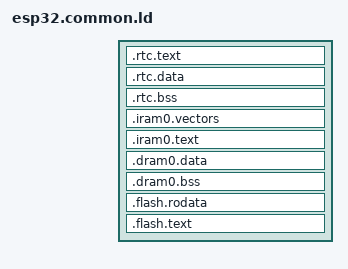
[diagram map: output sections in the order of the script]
/*  Default entry point:  */
ENTRY(call_start_cpu0);

SECTIONS
{
  /* RTC fast memory holds RTC wake stub code,
     including from any source file named rtc_wake_stub*.c
  */
  .rtc.text :
  {
    . = ALIGN(4);
    *(.rtc.literal .rtc.text)
    *rtc_wake_stub*.o(.literal .text .literal.* .text.*)
  } >rtc_iram_seg

  /* RTC slow memory holds RTC wake stub
     data/rodata, including from any source file
     named rtc_wake_stub*.c
  */
  .rtc.data :
  {
    _rtc_data_start = ABSOLUTE(.);
    *(.rtc.data)
    *(.rtc.rodata)
    *rtc_wake_stub*.o(.data .rodata .data.* .rodata.* .bss .bss.*)
    _rtc_data_end = ABSOLUTE(.);
  } > rtc_slow_seg

  /* RTC bss, from any source file named rtc_wake_stub*.c */
  .rtc.bss (NOLOAD) :
  {
    _rtc_bss_start = ABSOLUTE(.);
    *rtc_wake_stub*.o(.bss .bss.*)
    *rtc_wake_stub*.o(COMMON)
    _rtc_bss_end = ABSOLUTE(.);
  } > rtc_slow_seg

  /* Send .iram0 code to iram */
  .iram0.vectors :
  {
    /* Vectors go to IRAM */
    _init_start = ABSOLUTE(.);
    /* Vectors according to builds/RF-2015.2-win32/esp108_v1_2_s5_512int_2/config.html */
    . = 0x0;
    KEEP(*(.WindowVectors.text));
    . = 0x180;
    KEEP(*(.Level2InterruptVector.text));
    . = 0x1c0;
    KEEP(*(.Level3InterruptVector.text));
    . = 0x200;
    KEEP(*(.Level4InterruptVector.text));
    . = 0x240;
    KEEP(*(.Level5InterruptVector.text));
    . = 0x280;
    KEEP(*(.DebugExceptionVector.text));
    . = 0x2c0;
    KEEP(*(.NMIExceptionVector.text));
    . = 0x300;
    KEEP(*(.KernelExceptionVector.text));
    . = 0x340;
    KEEP(*(.UserExceptionVector.text));
    . = 0x3C0;
    KEEP(*(.DoubleExceptionVector.text));
    . = 0x400;
    *(.*Vector.literal)

    *(.UserEnter.literal);
    *(.UserEnter.text);
    . = ALIGN (16);
    *(.entry.text)
    *(.init.literal)
    *(.init)
    _init_end = ABSOLUTE(.);

    /* This goes here, not at top of linker script, so addr2line finds it last,
       and uses it in preference to the first symbol in IRAM */
    _iram_start = ABSOLUTE(0);
  } > iram0_0_seg

  .iram0.text :
  {
    /* Code marked as runnning out of IRAM */
    _iram_text_start = ABSOLUTE(.);
    *(.iram1 .iram1.*)
    *libfreertos.a:(.literal .text .literal.* .text.*)
    *libesp32.a:panic.o(.literal .text .literal.* .text.*)
    *libesp32.a:core_dump.o(.literal .text .literal.* .text.*)
    *libphy.a:(.literal .text .literal.* .text.*)
    *librtc.a:(.literal .text .literal.* .text.*)
    *librtc_clk.a:(.literal .text .literal.* .text.*)
    *libpp.a:pp.o(.literal .text .literal.* .text.*)
    *libpp.a:lmac.o(.literal .text .literal.* .text.*)
    *libpp.a:wdev.o(.literal .text .literal.* .text.*)
    *libcore.a:ets_timer.o(.literal .text .literal.* .text.*)
    *libnet80211.a:ieee80211_misc.o(.literal .text .literal.* .text.*)
    *libhal.a:(.literal .text .literal.* .text.*)
    *libcoexist.a:(.literal .text .literal.* .text.*)
    _iram_text_end = ABSOLUTE(.);
  } > iram0_0_seg

  .dram0.data :
  {
    _data_start = ABSOLUTE(.);
    KEEP(*(.data))
    KEEP(*(.data.*))
    KEEP(*(.gnu.linkonce.d.*))
    KEEP(*(.data1))
    KEEP(*(.sdata))
    KEEP(*(.sdata.*))
    KEEP(*(.gnu.linkonce.s.*))
    KEEP(*(.sdata2))
    KEEP(*(.sdata2.*))
    KEEP(*(.gnu.linkonce.s2.*))
    KEEP(*(.jcr))
    *(.dram1 .dram1.*)
    *libesp32.a:panic.o(.rodata .rodata.*)
    _data_end = ABSOLUTE(.);
    . = ALIGN(4);
  } >dram0_0_seg

  /* Shared RAM */
  .dram0.bss (NOLOAD) :
  {
    . = ALIGN (8);
    _bss_start = ABSOLUTE(.);
    *(.dynsbss)
    *(.sbss)
    *(.sbss.*)
    *(.gnu.linkonce.sb.*)
    *(.scommon)
    *(.sbss2)
    *(.sbss2.*)
    *(.gnu.linkonce.sb2.*)
    *(.dynbss)
    *(.bss)
    *(.bss.*)
    *(.share.mem)
    *(.gnu.linkonce.b.*)
    *(COMMON)
    . = ALIGN (8);
    _bss_end = ABSOLUTE(.);
    _heap_start = ABSOLUTE(.);
  } >dram0_0_seg

  .flash.rodata :
  {
    _rodata_start = ABSOLUTE(.);
    *(.rodata)
    *(.rodata.*)
    *(.irom1.text) /* catch stray ICACHE_RODATA_ATTR */
    *(.gnu.linkonce.r.*)
    *(.rodata1)
    __XT_EXCEPTION_TABLE_ = ABSOLUTE(.);
    *(.xt_except_table)
    *(.gcc_except_table)
    *(.gnu.linkonce.e.*)
    *(.gnu.version_r)
    *(.eh_frame)
    . = (. + 3) & ~ 3;
    /*  C++ constructor and destructor tables, properly ordered:  */
    __init_array_start = ABSOLUTE(.);
    KEEP (*crtbegin.o(.ctors))
    KEEP (*(EXCLUDE_FILE (*crtend.o) .ctors))
    KEEP (*(SORT(.ctors.*)))
    KEEP (*(.ctors))
    __init_array_end = ABSOLUTE(.);
    KEEP (*crtbegin.o(.dtors))
    KEEP (*(EXCLUDE_FILE (*crtend.o) .dtors))
    KEEP (*(SORT(.dtors.*)))
    KEEP (*(.dtors))
    /*  C++ exception handlers table:  */
    __XT_EXCEPTION_DESCS_ = ABSOLUTE(.);
    *(.xt_except_desc)
    *(.gnu.linkonce.h.*)
    __XT_EXCEPTION_DESCS_END__ = ABSOLUTE(.);
    *(.xt_except_desc_end)
    *(.dynamic)
    *(.gnu.version_d)
    _rodata_end = ABSOLUTE(.);
    /* Literals are also RO data. */
    _lit4_start = ABSOLUTE(.);
    *(*.lit4)
    *(.lit4.*)
    *(.gnu.linkonce.lit4.*)
    _lit4_end = ABSOLUTE(.);
    . = ALIGN(4);
  } >drom0_0_seg

  .flash.text :
  {
    _stext = .;
    _text_start = ABSOLUTE(.);
    *(.literal .text .literal.* .text.* .stub .gnu.warning .gnu.linkonce.literal.* .gnu.linkonce.t.*.literal .gnu.linkonce.t.*)
    *(.irom0.text) /* catch stray ICACHE_RODATA_ATTR */
    *(.fini.literal)
    *(.fini)
    *(.gnu.version)
    _text_end = ABSOLUTE(.);
    _etext = .;

    /* Similar to _iram_start, this symbol goes here so it is
       resolved by addr2line in preference to the first symbol in
       the flash.text segment.
    */
    _flash_cache_start = ABSOLUTE(0);
  } >iram0_2_seg
}
